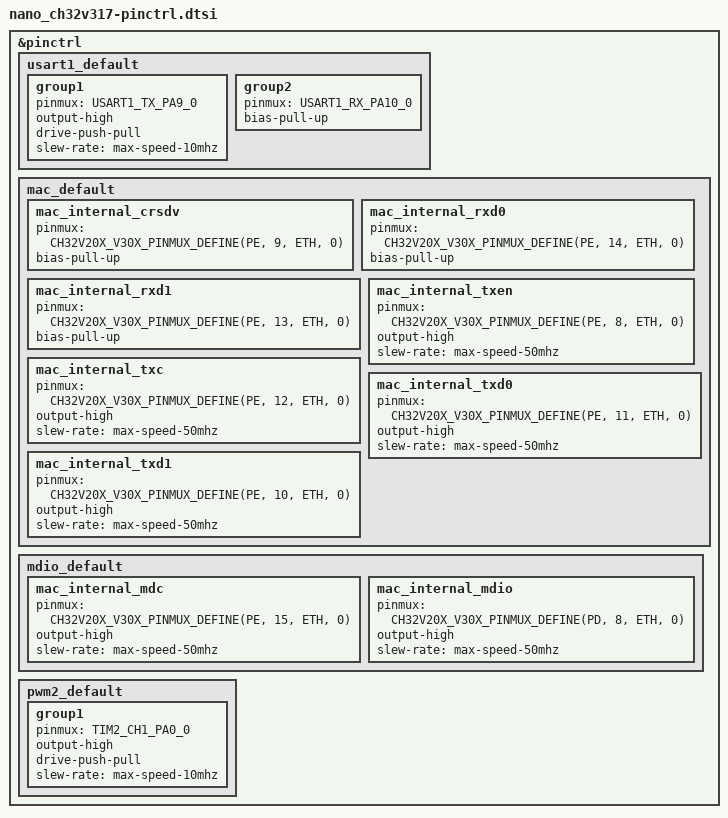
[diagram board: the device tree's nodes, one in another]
/*
 * Copyright (c) 2026 James Bennion-Pedley
 * SPDX-License-Identifier: Apache-2.0
 */

#include <zephyr/dt-bindings/pinctrl/ch32v20x_30x-pinctrl.h>

&pinctrl {
	usart1_default: usart1_default {
		group1 {
			pinmux = <USART1_TX_PA9_0>;
			output-high;
			drive-push-pull;
			slew-rate = "max-speed-10mhz";
		};

		group2 {
			pinmux = <USART1_RX_PA10_0>;
			bias-pull-up;
		};
	};

	mac_default: mac_default {
		mac_internal_crsdv {
			pinmux = <CH32V20X_V30X_PINMUX_DEFINE(PE, 9, ETH, 0)>;
			bias-pull-up;
		};

		mac_internal_rxd0 {
			pinmux = <CH32V20X_V30X_PINMUX_DEFINE(PE, 14, ETH, 0)>;
			bias-pull-up;
		};

		mac_internal_rxd1 {
			pinmux = <CH32V20X_V30X_PINMUX_DEFINE(PE, 13, ETH, 0)>;
			bias-pull-up;
		};

		mac_internal_txen {
			pinmux = <CH32V20X_V30X_PINMUX_DEFINE(PE, 8, ETH, 0)>;
			output-high;
			slew-rate = "max-speed-50mhz";
		};

		mac_internal_txc {
			pinmux = <CH32V20X_V30X_PINMUX_DEFINE(PE, 12, ETH, 0)>;
			output-high;
			slew-rate = "max-speed-50mhz";
		};

		mac_internal_txd0 {
			pinmux = <CH32V20X_V30X_PINMUX_DEFINE(PE, 11, ETH, 0)>;
			output-high;
			slew-rate = "max-speed-50mhz";
		};

		mac_internal_txd1 {
			pinmux = <CH32V20X_V30X_PINMUX_DEFINE(PE, 10, ETH, 0)>;
			output-high;
			slew-rate = "max-speed-50mhz";
		};
	};

	mdio_default: mdio_default {
		mac_internal_mdc {
			pinmux = <CH32V20X_V30X_PINMUX_DEFINE(PE, 15, ETH, 0)>;
			output-high;
			slew-rate = "max-speed-50mhz";
		};

		mac_internal_mdio {
			pinmux = <CH32V20X_V30X_PINMUX_DEFINE(PD, 8, ETH, 0)>;
			output-high;
			slew-rate = "max-speed-50mhz";
		};
	};

	pwm2_default: pwm2_default {
		group1 {
			pinmux = <TIM2_CH1_PA0_0>;
			output-high;
			drive-push-pull;
			slew-rate = "max-speed-10mhz";
		};
	};
};
